AUTOSAR XML (schema 00046)
package /SWComponent
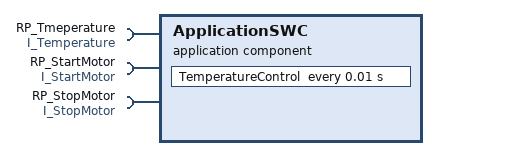
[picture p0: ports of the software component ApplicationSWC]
  application sw component type ApplicationSWC
    require port RP_Tmeperature: required-interface=I_Temperature
    require port RP_StartMotor: required-interface=I_StartMotor
    require port RP_StopMotor: required-interface=I_StopMotor
    behavior IB_SWC
      timing event TE_10ms: start-on-event=TemperatureControl, period=0.01
      runnable TemperatureControl: symbol=App_TemperatureControl
        data-receive-point-by-arguments:
          access VA_Temp: accessed-variable=RP_Tmeperature.Temperature
        sync call SC_StartMotor: operation=RP_StartMotor.StartMotor
        sync call SC_StopMotor: operation=RP_StopMotor.StopMotor
